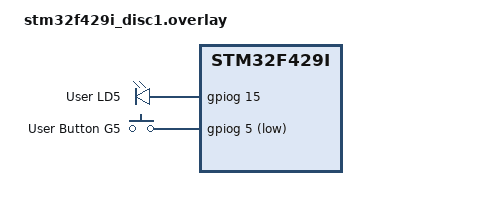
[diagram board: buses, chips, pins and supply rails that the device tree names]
/ {
	leds {
		compatible = "gpio-leds";

		external_led_5: led_5 {
			gpios = <&gpiog 15 GPIO_ACTIVE_HIGH>;
			label = "User LD5";
		};
	};

	buttons {
		compatible = "gpio-keys";
		polling-mode;

		button_1: button {
			gpios = <&gpiog 5 GPIO_ACTIVE_LOW>;
			label = "User Button G5";
		};
	};

	aliases {
		led2 = &external_led_5;
		my-button = &button_1;
	};
};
